# dm648_cslr_cpsgmii register map
Vendor: Texas Instruments
Peripheral module from a debugger description file.
Registers are 32-bit, access not given, reset 0x0 unless marked. A register's access mark holds for its fields unless they carry their own. Offsets are as the file gives them; lines under a group give offsets from that group; [hi:lo] are bit positions; {n}, {i} and the like mark numbered series; 'fields as' and 'values as' point back to an identical list; <NAME> marks a mode.

## CPSGMII
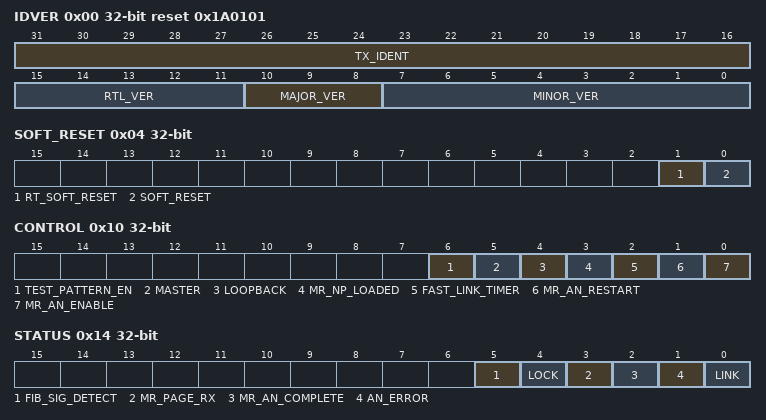
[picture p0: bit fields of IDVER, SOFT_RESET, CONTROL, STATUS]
0x00 IDVER ro reset 0x1A0101 — version id register
  [31:16] TX_IDENT — TX Identification value
  [15:11] RTL_VER — RTL_version register
  [10:8] MAJOR_VER — Major version register
  [7:0] MINOR_VER — Minor Version register
0x04 SOFT_RESET
  [1] RT_SOFT_RESET rw — Transmit and Receive Software Reset  Writing a one to this bit causes the CPSGMII transmit and receive logic to be in the reset condition (the vbusp_clk domain is not reset). The reset condition is removed when a zero is written to this bit. This bit is intended to be used when changing between loopback mode and normal mode of operation.
  [0] SOFT_RESET rw — Software Reset  Writing a one to this bit causes the CPSGMII logic to be reset. Software reset occurs immediately. This bit reads as a zero.
0x10 CONTROL
  [6] TEST_PATTERN_EN rw — Test Pattern Enable  force the output of K28.5 on TX_ENC for test purposes. 0  Normal operation 1  Forced K28.5 on transmit output
  [5] MASTER rw — Master Mode  0  Slave Mode 1  Master mode  Set to one for one side of a direct connection. When this bit is set, the control logic uses the Mr_Adv_Ability register to determine speed and duplexity instead of the Mr_Lp_Adv_Ability register. Master mode allows a CPSGMII direct connection with auto-negotation or with a forced link.
    0=?
  [4] LOOPBACK rw — Loopback mode  0  Not in internal loopback mode 1  Internal loopback mode. The transmit clock (TX_CLK) is used for transmit and receive.
  [3] MR_NP_LOADED rw — Next Page Loaded  Writing a one to this bit informs the auto-negotation process that the next page register has been loaded. This bit is cleared by the auto-negotation state machine before the mr_page_rx status bit is set. This bit is not used when the SGMII_MODE input is asserted.
  [2] FAST_LINK_TIMER rw — Fast Link Timer  0  The link timer value is 10ms in FIBER mode and 1.6ms in SGMII mode. 1  The link timer value is 2us in FIBER and SGMII mode. This is included for test purposes.
  [1] MR_AN_RESTART rw — Auto-Negotiation Restart  Writing a one and then a zero to this bit causes the auto-negotiation process to be restarted.
  [0] MR_AN_ENABLE rw — Auto-Negotiation Enable  Writing a one to this bit enables the autonegotiation process.
    0=?; 0=?
0x14 STATUS
  [5] FIB_SIG_DETECT ro — Fiber Signal Detect  This is the FIB_SIG_DETECT input pin.
  [4] LOCK ro — Lock  This is the LOCK input pin.
  [3] MR_PAGE_RX ro — Next Page Received  This bit is set to one by the auto-negotation state machine when the next page has been received. This bit is cleared to zero by a host write of a one to the mr_np_loaded bit in the Control register. This value is not valid until the lock status bit is asserted.
  [2] MR_AN_COMPLETE ro — Auto-negotiation complete. This value is not valid until the lock status bit is asserted. 0  auto-negotation is not complete 1  auto-negotation is completed.
    0=?
  [1] AN_ERROR ro — Auto-negotiation error. For SGMII mode, an autonegotation error occurs when halfduplex gigabit is commanded. For FIBER mode, an autonegotation error occurs if both sides cannot be fullduplex. This value is not valid until the lock status bit is asserted. 0  no auto-negotation error 1  auto-negotation error
  [0] LINK ro — Link indicator - This value is not valid until the lock status bit is asserted. 0  Link is not up. 1  Link is up.
0x18 MR_ADV_ABILITY — Advertised ability register
  [15:0] MR_ADV_ABILITY rw — Advertised Ability  When in FIBER mode, this value corresponds to the mr_adv_ability[16:1] in the IEEE specification and is loaded into the IEEE specification tx_config_reg[15:0]. When in SGMII mode, this value corresponds to the tx_config_reg[15:0] register value in the Serial-GMII specification.
    0=?
0x1C MR_NP_TX — Transmit Next page register
  [15:0] MR_NP_TX rw — Next Page Transmit This value corresponds to the mr_np_tx[16:1] value in the IEEE specification. Next page is used only in FIBER mode.
    0=?
0x20 MR_LP_ADV_ABILITY — Link Partner Advertised ability
  [15:0] MR_LP_ADV_ABILITY rw — Link Partner Advertised Ability  readable when auto-negotation is complete. When in FIBER mode, this value corresponds to the mr_lp_adv_ability[16:1] in the IEEE. When in SGMII mode, this value corresponds to the tx_config_reg[15:0] register value in the Serial-GMII specification.
    0=?; 0=?
0x24 MR_NP_RX — Link Partner Next page Received Register
  [15:0] MR_NP_RX rw — Link Partner Next Page Received  Readable when the next page is received. These bits are as defined in the IEEE 802.3 standard. Next page is used only in FIBER mode.
0x30 TX_CFG rw — Transmit Configuration Register
  [31:0] TX_CFG — Transmit Configuration Register Output  This is a 32-bit general purpose output intended to be used to control the SERDES transmit configuration. These are SERDES device specific configuration bits.
0x34 RX_CFG rw — Receive Configuration Register
  [31:0] RX_CFG — Receive Configuration Register Output - This is a 32-bit general purpose output intended to be used to control the SERDES receive configuration. These are SERDES device specific configuration bits.
0x38 AUX_CFG rw — Auxiliary Configuration Register
  [31:0] AUX_CFG — Auxiliary Configuration Register Output - This is a 32-bit general purpose output intended to be used to control the SERDES PLL configuration. These are SERDES device specific configuration bits.
0x40 DIAG_CLEAR — Diagnostics Clear Register
  [0] DIAG_CLEAR rw — Diagnostics Clear  Clears all diagnostic status bits when set to one. Some bits may be set back to one immediately following reset. The reset requires several clocks due to synchronizers.
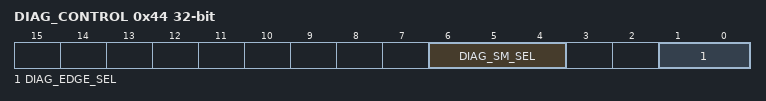
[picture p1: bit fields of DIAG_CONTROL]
0x44 DIAG_CONTROL — Diagnostics Control Register
  [6:4] DIAG_SM_SEL rw — Diagnostic Select  Determines which internal diagnostic bits are muxed onto diag_status[15:0]. 000  Reserved 001  Diagnostic Hold Signals 010  Diagnostic Sync Status (sync_sm state machine) 011  Diagnostic AN Status (amsm state machine) 100  Diagnostic TXOS Status (txos state machine) 101  Diagnostic TXCG Status (txcg state machine) 110  Diagnostic RXSM Status (rxsm state machine lower bits) 111  Diagnostic RXSM Status (rxsm state machine upper bits)
  [1:0] DIAG_EDGE_SEL rw — Diagnostis Hold Signals Edge Select 00  Diagnostic Hold Signals Level 01  Diagnostic Hold Signals rising edge detected 10  Diagnostic Hold Signals falling edge detected 11  Diagnostic Hold Signals ether (both) edge detected
0x48 DIAG_STATUS — Diagnostics Status
  [15:0] DIAG_STATUS rw
